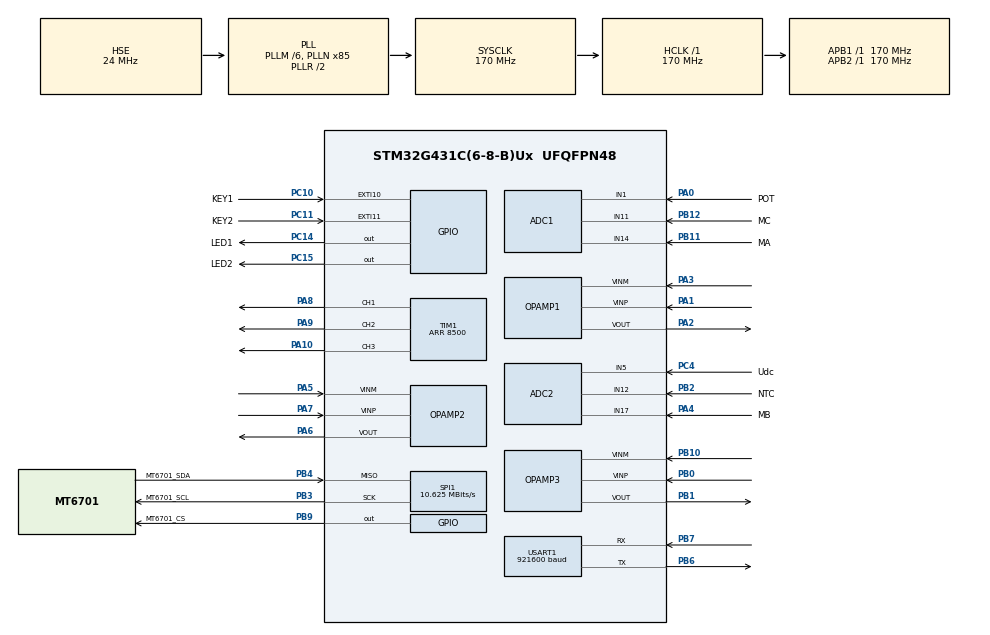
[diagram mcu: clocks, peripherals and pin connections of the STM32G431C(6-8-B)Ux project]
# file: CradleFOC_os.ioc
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ADC1.Channel-0\#ChannelRegularConversion=ADC_CHANNEL_1
ADC1.Channel-1\#ChannelRegularConversion=ADC_CHANNEL_11
ADC1.Channel-2\#ChannelRegularConversion=ADC_CHANNEL_14
ADC1.ClockPrescaler=ADC_CLOCK_ASYNC_DIV6
ADC1.ContinuousConvMode=DISABLE
ADC1.DMAContinuousRequests=ENABLE
ADC1.EnableInjectedConversion=ENABLE
ADC1.ExternalTrigConv=ADC_EXTERNALTRIG_T2_CC2
ADC1.ExternalTrigInjecConv=ADC_EXTERNALTRIGINJEC_T1_CC4
ADC1.InjNumberOfConversion=2
ADC1.InjectedChannel-3\#ChannelInjectedConversion=ADC_CHANNEL_3
ADC1.InjectedChannel-4\#ChannelInjectedConversion=ADC_CHANNEL_12
ADC1.InjectedOffsetNumber-3\#ChannelInjectedConversion=ADC_OFFSET_NONE
ADC1.InjectedOffsetNumber-4\#ChannelInjectedConversion=ADC_OFFSET_NONE
ADC1.InjectedRank-3\#ChannelInjectedConversion=1
ADC1.InjectedRank-4\#ChannelInjectedConversion=2
ADC1.InjectedSamplingTime-3\#ChannelInjectedConversion=ADC_SAMPLETIME_12CYCLES_5
ADC1.InjectedSamplingTime-4\#ChannelInjectedConversion=ADC_SAMPLETIME_12CYCLES_5
ADC1.NbrOfConversion=3
ADC1.NbrOfConversionFlag=1
ADC1.OffsetNumber-0\#ChannelRegularConversion=ADC_OFFSET_NONE
ADC1.OffsetNumber-1\#ChannelRegularConversion=ADC_OFFSET_NONE
ADC1.OffsetNumber-2\#ChannelRegularConversion=ADC_OFFSET_NONE
ADC1.Rank-0\#ChannelRegularConversion=1
ADC1.Rank-1\#ChannelRegularConversion=2
ADC1.Rank-2\#ChannelRegularConversion=3
ADC1.Rank1_Channel=ADC_CHANNEL_3
ADC1.Rank2_Channel=ADC_CHANNEL_12
ADC1.SamplingTime-0\#ChannelRegularConversion=ADC_SAMPLETIME_12CYCLES_5
ADC1.SamplingTime-1\#ChannelRegularConversion=ADC_SAMPLETIME_12CYCLES_5
ADC1.SamplingTime-2\#ChannelRegularConversion=ADC_SAMPLETIME_12CYCLES_5
ADC1.master=1
ADC2.Channel-0\#ChannelRegularConversion=ADC_CHANNEL_5
ADC2.Channel-1\#ChannelRegularConversion=ADC_CHANNEL_12
ADC2.Channel-2\#ChannelRegularConversion=ADC_CHANNEL_17
ADC2.ClockPrescaler=ADC_CLOCK_ASYNC_DIV6
ADC2.ContinuousConvMode=DISABLE
ADC2.DMAContinuousRequests=ENABLE
ADC2.EnableInjectedConversion=ENABLE
ADC2.ExternalTrigConv=ADC_EXTERNALTRIG_T2_CC2
ADC2.ExternalTrigInjecConv=ADC_EXTERNALTRIGINJEC_T1_CC4
ADC2.InjNumberOfConversion=1
ADC2.InjectedChannel-3\#ChannelInjectedConversion=ADC_CHANNEL_3
ADC2.InjectedOffsetNumber-3\#ChannelInjectedConversion=ADC_OFFSET_NONE
ADC2.InjectedRank-3\#ChannelInjectedConversion=1
ADC2.InjectedSamplingTime-3\#ChannelInjectedConversion=ADC_SAMPLETIME_12CYCLES_5
ADC2.NbrOfConversion=3
ADC2.NbrOfConversionFlag=1
ADC2.OffsetNumber-0\#ChannelRegularConversion=ADC_OFFSET_NONE
ADC2.OffsetNumber-1\#ChannelRegularConversion=ADC_OFFSET_NONE
ADC2.OffsetNumber-2\#ChannelRegularConversion=ADC_OFFSET_NONE
ADC2.Rank-0\#ChannelRegularConversion=1
ADC2.Rank-1\#ChannelRegularConversion=2
ADC2.Rank-2\#ChannelRegularConversion=3
ADC2.Rank1_Channel=ADC_CHANNEL_3
ADC2.SamplingTime-0\#ChannelRegularConversion=ADC_SAMPLETIME_12CYCLES_5
ADC2.SamplingTime-1\#ChannelRegularConversion=ADC_SAMPLETIME_12CYCLES_5
ADC2.SamplingTime-2\#ChannelRegularConversion=ADC_SAMPLETIME_12CYCLES_5
Dma.ADC1.1.Direction=DMA_PERIPH_TO_MEMORY
Dma.ADC1.1.EventEnable=DISABLE
Dma.ADC1.1.Instance=DMA1_Channel2
Dma.ADC1.1.MemDataAlignment=DMA_MDATAALIGN_HALFWORD
Dma.ADC1.1.MemInc=DMA_MINC_ENABLE
Dma.ADC1.1.Mode=DMA_CIRCULAR
Dma.ADC1.1.PeriphDataAlignment=DMA_PDATAALIGN_HALFWORD
Dma.ADC1.1.PeriphInc=DMA_PINC_DISABLE
Dma.ADC1.1.Polarity=HAL_DMAMUX_REQ_GEN_RISING
Dma.ADC1.1.Priority=DMA_PRIORITY_LOW
Dma.ADC1.1.RequestNumber=1
Dma.ADC1.1.SignalID=NONE
Dma.ADC1.1.SyncEnable=DISABLE
Dma.ADC1.1.SyncPolarity=HAL_DMAMUX_SYNC_NO_EVENT
Dma.ADC1.1.SyncRequestNumber=1
Dma.ADC1.1.SyncSignalID=NONE
Dma.ADC2.2.Direction=DMA_PERIPH_TO_MEMORY
Dma.ADC2.2.EventEnable=DISABLE
Dma.ADC2.2.Instance=DMA1_Channel3
Dma.ADC2.2.MemDataAlignment=DMA_MDATAALIGN_HALFWORD
Dma.ADC2.2.MemInc=DMA_MINC_ENABLE
Dma.ADC2.2.Mode=DMA_CIRCULAR
Dma.ADC2.2.PeriphDataAlignment=DMA_PDATAALIGN_HALFWORD
Dma.ADC2.2.PeriphInc=DMA_PINC_DISABLE
Dma.ADC2.2.Polarity=HAL_DMAMUX_REQ_GEN_RISING
Dma.ADC2.2.Priority=DMA_PRIORITY_LOW
Dma.ADC2.2.RequestNumber=1
Dma.ADC2.2.SignalID=NONE
Dma.ADC2.2.SyncEnable=DISABLE
Dma.ADC2.2.SyncPolarity=HAL_DMAMUX_SYNC_NO_EVENT
Dma.ADC2.2.SyncRequestNumber=1
Dma.ADC2.2.SyncSignalID=NONE
Dma.Request0=USART1_TX
Dma.Request1=ADC1
Dma.Request2=ADC2
Dma.USART1_TX.0.Direction=DMA_MEMORY_TO_PERIPH
Dma.USART1_TX.0.EventEnable=DISABLE
Dma.USART1_TX.0.Instance=DMA1_Channel1
Dma.USART1_TX.0.MemDataAlignment=DMA_MDATAALIGN_BYTE
Dma.USART1_TX.0.MemInc=DMA_MINC_ENABLE
Dma.USART1_TX.0.Mode=DMA_NORMAL
Dma.USART1_TX.0.PeriphDataAlignment=DMA_PDATAALIGN_BYTE
Dma.USART1_TX.0.PeriphInc=DMA_PINC_DISABLE
Dma.USART1_TX.0.Polarity=HAL_DMAMUX_REQ_GEN_RISING
Dma.USART1_TX.0.Priority=DMA_PRIORITY_LOW
Dma.USART1_TX.0.RequestNumber=1
Dma.USART1_TX.0.SignalID=NONE
Dma.USART1_TX.0.SyncEnable=DISABLE
Dma.USART1_TX.0.SyncPolarity=HAL_DMAMUX_SYNC_NO_EVENT
Dma.USART1_TX.0.SyncRequestNumber=1
Dma.USART1_TX.0.SyncSignalID=NONE
FREERTOS.INCLUDE_uxTaskGetStackHighWaterMark=1
FREERTOS.Tasks01=defaultTask,0,64,StartDefaultTask,Default,NULL,Dynamic,NULL,NULL;myTask02_LOG,-2,300,FOC_LOG,Default,NULL,Dynamic,NULL,NULL;myTask03_KEY,-2,64,KEY_USER,Default,NULL,Dynamic,NULL,NULL;myTask04_FOC,-1,200,FOC,Default,NULL,Dynamic,NULL,NULL
FREERTOS.configENABLE_FPU=1
FREERTOS.configMINIMAL_STACK_SIZE=64
FREERTOS.configTOTAL_HEAP_SIZE=5000
Mcu.Family=STM32G4
Mcu.Name=STM32G431C(6-8-B)Ux
Mcu.Package=UFQFPN48
NVIC.ADC1_2_IRQn=true\:5\:0\:false\:false\:true\:true\:true\:true\:true
NVIC.DMA1_Channel1_IRQn=true\:5\:0\:false\:false\:true\:true\:false\:true\:true
NVIC.DMA1_Channel2_IRQn=true\:5\:0\:false\:false\:true\:true\:false\:true\:true
NVIC.DMA1_Channel3_IRQn=true\:5\:0\:false\:false\:true\:true\:false\:true\:true
NVIC.EXTI15_10_IRQn=true\:5\:0\:false\:false\:true\:true\:true\:true\:true
NVIC.PriorityGroup=NVIC_PRIORITYGROUP_4
NVIC.TIM3_IRQn=true\:15\:0\:false\:false\:true\:false\:false\:true\:true
NVIC.TimeBase=TIM3_IRQn
NVIC.TimeBaseIP=TIM3
NVIC.USART1_IRQn=true\:5\:0\:false\:false\:true\:true\:true\:true\:true
PA0.GPIO_Label=POT
PA0.Mode=IN1-Single-Ended
PA0.Signal=ADC1_IN1
PA1.Mode=Standalone
PA1.Signal=OPAMP1_VINP
PA10.Signal=S_TIM1_CH3
PA13.Mode=Serial_Wire
PA13.Signal=SYS_JTMS-SWDIO
PA14.Mode=Serial_Wire
PA14.Signal=SYS_JTCK-SWCLK
PA2.Signal=SharedAnalog_PA2
PA3.Mode=Standalone
PA3.Signal=OPAMP1_VINM
PA4.GPIO_Label=MB
PA4.Mode=IN17-Single-Ended
PA4.Signal=ADC2_IN17
PA5.Mode=Standalone
PA5.Signal=OPAMP2_VINM
PA6.Signal=SharedAnalog_PA6
PA7.Mode=Standalone
PA7.Signal=OPAMP2_VINP
PA8.Signal=S_TIM1_CH1
PA9.Signal=S_TIM1_CH2
PB0.Mode=Standalone
PB0.Signal=OPAMP3_VINP
PB1.Signal=SharedAnalog_PB1
PB10.Mode=Standalone
PB10.Signal=OPAMP3_VINM
PB11.GPIO_Label=MA
PB11.Mode=IN14-Single-Ended
PB11.Signal=ADC1_IN14
PB12.GPIO_Label=MC
PB12.Mode=IN11-Single-Ended
PB12.Signal=ADC1_IN11
PB2.GPIO_Label=NTC
PB2.Mode=IN12-Single-Ended
PB2.Signal=ADC2_IN12
PB3.GPIO_Label=MT6701_SCL
PB3.Mode=RX_Only_Simplex_Unidirect_Master
PB3.Signal=SPI1_SCK
PB4.GPIO_Label=MT6701_SDA
PB4.Mode=RX_Only_Simplex_Unidirect_Master
PB4.Signal=SPI1_MISO
PB6.Mode=Asynchronous
PB6.Signal=USART1_TX
PB7.Mode=Asynchronous
PB7.Signal=USART1_RX
PB9.GPIO_Label=MT6701_CS
PB9.GPIO_Speed=GPIO_SPEED_FREQ_HIGH
PB9.PinState=GPIO_PIN_SET
PB9.Signal=GPIO_Output
PC10.GPIO_Label=KEY1
PC10.GPIO_ModeDefaultEXTI=GPIO_MODE_IT_FALLING
PC10.Signal=GPXTI10
PC11.GPIO_Label=KEY2
PC11.GPIO_ModeDefaultEXTI=GPIO_MODE_IT_FALLING
PC11.Signal=GPXTI11
PC14-OSC32_IN.GPIO_Label=LED1
PC14-OSC32_IN.PinState=GPIO_PIN_SET
PC14-OSC32_IN.Signal=GPIO_Output
PC15-OSC32_OUT.GPIO_Label=LED2
PC15-OSC32_OUT.PinState=GPIO_PIN_SET
PC15-OSC32_OUT.Signal=GPIO_Output
PC4.GPIO_Label=Udc
PC4.Mode=IN5-Single-Ended
PC4.Signal=ADC2_IN5
PF0-OSC_IN.Mode=HSE-External-Oscillator
PF0-OSC_IN.Signal=RCC_OSC_IN
PF1-OSC_OUT.Mode=HSE-External-Oscillator
PF1-OSC_OUT.Signal=RCC_OSC_OUT
ProjectManager.HeapSize=0x200
ProjectManager.StackSize=0x400
ProjectManager.TargetToolchain=STM32CubeIDE
RCC.ADC12Freq_Value=170000000
RCC.AHBFreq_Value=170000000
RCC.APB1Freq_Value=170000000
RCC.APB1TimFreq_Value=170000000
RCC.APB2Freq_Value=170000000
RCC.APB2TimFreq_Value=170000000
RCC.CortexFreq_Value=170000000
RCC.EXTERNAL_CLOCK_VALUE=12288000
RCC.HCLKFreq_Value=170000000
RCC.HSE_VALUE=24000000
RCC.HSI48_VALUE=48000000
RCC.HSI_VALUE=16000000
RCC.LSE_VALUE=32768
RCC.PLLM=RCC_PLLM_DIV6
RCC.PLLN=85
RCC.PLLSourceVirtual=RCC_PLLSOURCE_HSE
RCC.SYSCLKFreq_VALUE=170000000
RCC.SYSCLKSource=RCC_SYSCLKSOURCE_PLLCLK
RCC.USBFreq_Value=170000000
RCC.VCOOutputFreq_Value=340000000
SH.S_TIM1_CH1.0=TIM1_CH1,PWM Generation1 CH1
SH.S_TIM1_CH2.0=TIM1_CH2,PWM Generation2 CH2
SH.S_TIM1_CH3.0=TIM1_CH3,PWM Generation3 CH3
SH.SharedAnalog_PA2.0=OPAMP1_VOUT,Standalone
SH.SharedAnalog_PA2.1=ADC1_IN3,IN3-Single-Ended
SH.SharedAnalog_PA6.0=OPAMP2_VOUT,Standalone
SH.SharedAnalog_PA6.1=ADC2_IN3,IN3-Single-Ended
SH.SharedAnalog_PB1.0=OPAMP3_VOUT,Standalone
SH.SharedAnalog_PB1.1=ADC1_IN12,IN12-Single-Ended
SPI1.BaudRatePrescaler=SPI_BAUDRATEPRESCALER_16
SPI1.CLKPhase=SPI_PHASE_2EDGE
SPI1.CalculateBaudRate=10.625 MBits/s
SPI1.DataSize=SPI_DATASIZE_16BIT
SPI1.Direction=SPI_DIRECTION_2LINES_RXONLY
SPI1.Mode=SPI_MODE_MASTER
SPI1.VirtualType=VM_MASTER
STMicroelectronics.X-CUBE-ALGOBUILD.1.3.0.LibraryCcDSPOoLibraryJjDSPOoLibrary=true
TIM1.Channel-PWM\ Generation1\ CH1=TIM_CHANNEL_1
TIM1.Channel-PWM\ Generation2\ CH2=TIM_CHANNEL_2
TIM1.Channel-PWM\ Generation3\ CH3=TIM_CHANNEL_3
TIM1.Channel-PWM\ Generation4\ No\ Output=TIM_CHANNEL_4
TIM1.CounterMode=TIM_COUNTERMODE_CENTERALIGNED1
TIM1.OCMode_PWM-PWM\ Generation4\ No\ Output=TIM_OCMODE_PWM2
TIM1.PeriodNoDither=8500
TIM1.RepetitionCounter=1
TIM1.TIM_MasterOutputTrigger=TIM_TRGO_OC4REF
TIM2.Channel-PWM\ Generation2\ No\ Output=TIM_CHANNEL_2
TIM2.OCMode_PWM-PWM\ Generation2\ No\ Output=TIM_OCMODE_PWM2
TIM2.PeriodNoDither=1000-1
TIM2.Prescaler=170-1
TIM2.TIM_MasterOutputTrigger=TIM_TRGO_OC2REF
USART1.BaudRate=921600
USART1.VirtualMode-Asynchronous=VM_ASYNC
VP_FREERTOS_VS_CMSIS_V1.Mode=CMSIS_V1
VP_STMicroelectronics.X-CUBE-ALGOBUILD_VS_DSPOoLibraryJjLibrary_1.3.0_1.3.0.Mode=DSPOoLibraryJjLibrary
VP_SYS_VS_DBSignals.Mode=DisableDeadBatterySignals
VP_SYS_VS_tim3.Mode=TIM3
VP_TIM1_VS_ClockSourceINT.Mode=Internal
VP_TIM1_VS_no_output4.Mode=PWM Generation4 No Output
VP_TIM2_VS_ClockSourceINT.Mode=Internal
VP_TIM2_VS_no_output2.Mode=PWM Generation2 No Output
board=custom

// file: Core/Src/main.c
/* USER CODE BEGIN Header */
/**
  ******************************************************************************
  * @file           : main.c
  * @brief          : Main program body
  ******************************************************************************
  * @attention
  *
  * Copyright (c) 2024 STMicroelectronics.
  * All rights reserved.
  *
  * This software is licensed under terms that can be found in the LICENSE file
  * in the root directory of this software component.
  * If no LICENSE file comes with this software, it is provided AS-IS.
  *
  ******************************************************************************
  */
/* USER CODE END Header */
#include "main.h"
#include "cmsis_os.h"
#include "adc.h"
#include "dma.h"
#include "opamp.h"
#include "spi.h"
#include "tim.h"
#include "usart.h"
#include "gpio.h"

void SystemClock_Config(void);
void MX_FREERTOS_Init(void);

int main(void)
{

  /* MCU Configuration--------------------------------------------------------*/

  /* Reset of all peripherals, Initializes the Flash interface and the Systick. */
  HAL_Init();

  /* Configure the system clock */
  SystemClock_Config();

  /* Initialize all configured peripherals */
  MX_GPIO_Init();
  MX_DMA_Init();
  MX_USART1_UART_Init();
  MX_TIM1_Init();
  MX_SPI1_Init();
  MX_ADC1_Init();
  MX_ADC2_Init();
  MX_TIM2_Init();
  MX_OPAMP1_Init();
  MX_OPAMP2_Init();
  MX_OPAMP3_Init();

  /* Call init function for freertos objects (in freertos.c) */
  MX_FREERTOS_Init();

  /* Start scheduler */
  osKernelStart();

  /* We should never get here as control is now taken by the scheduler */
  /* Infinite loop */
  while (1)
  {

  }
}

void SystemClock_Config(void)
{
  RCC_OscInitTypeDef RCC_OscInitStruct = {0};
  RCC_ClkInitTypeDef RCC_ClkInitStruct = {0};

  /** Configure the main internal regulator output voltage
  */
  HAL_PWREx_ControlVoltageScaling(PWR_REGULATOR_VOLTAGE_SCALE1_BOOST);

  /** Initializes the RCC Oscillators according to the specified parameters
  * in the RCC_OscInitTypeDef structure.
  */
  RCC_OscInitStruct.OscillatorType = RCC_OSCILLATORTYPE_HSE;
  RCC_OscInitStruct.HSEState = RCC_HSE_ON;
  RCC_OscInitStruct.PLL.PLLState = RCC_PLL_ON;
  RCC_OscInitStruct.PLL.PLLSource = RCC_PLLSOURCE_HSE;
  RCC_OscInitStruct.PLL.PLLM = RCC_PLLM_DIV6;
  RCC_OscInitStruct.PLL.PLLN = 85;
  RCC_OscInitStruct.PLL.PLLP = RCC_PLLP_DIV2;
  RCC_OscInitStruct.PLL.PLLQ = RCC_PLLQ_DIV2;
  RCC_OscInitStruct.PLL.PLLR = RCC_PLLR_DIV2;
  if (HAL_RCC_OscConfig(&RCC_OscInitStruct) != HAL_OK)
  {
    Error_Handler();
  }

  /** Initializes the CPU, AHB and APB buses clocks
  */
  RCC_ClkInitStruct.ClockType = RCC_CLOCKTYPE_HCLK|RCC_CLOCKTYPE_SYSCLK
                              |RCC_CLOCKTYPE_PCLK1|RCC_CLOCKTYPE_PCLK2;
  RCC_ClkInitStruct.SYSCLKSource = RCC_SYSCLKSOURCE_PLLCLK;
  RCC_ClkInitStruct.AHBCLKDivider = RCC_SYSCLK_DIV1;
  RCC_ClkInitStruct.APB1CLKDivider = RCC_HCLK_DIV1;
  RCC_ClkInitStruct.APB2CLKDivider = RCC_HCLK_DIV1;

  if (HAL_RCC_ClockConfig(&RCC_ClkInitStruct, FLASH_LATENCY_4) != HAL_OK)
  {
    Error_Handler();
  }
}

void HAL_TIM_PeriodElapsedCallback(TIM_HandleTypeDef *htim)
{
  if (htim->Instance == TIM3) {
    HAL_IncTick();
  }
}

void Error_Handler(void)
{
  __disable_irq();
  while (1)
  {
  }
}

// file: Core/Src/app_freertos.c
/* USER CODE BEGIN Header */
/**
  ******************************************************************************
  * File Name          : app_freertos.c
  * Description        : Code for freertos applications
  ******************************************************************************
  * @attention
  *
  * Copyright (c) 2024 STMicroelectronics.
  * All rights reserved.
  *
  * This software is licensed under terms that can be found in the LICENSE file
  * in the root directory of this software component.
  * If no LICENSE file comes with this software, it is provided AS-IS.
  *
  ******************************************************************************
  */
/* USER CODE END Header */

#include "FreeRTOS.h"
#include "task.h"
#include "main.h"
#include "cmsis_os.h"

/* USER CODE BEGIN Includes */
#include "UserAPP.h"
#include "Serial.h"
/* USER CODE END Includes */

osThreadId defaultTaskHandle;
osThreadId myTask02_LOGHandle;
osThreadId myTask03_KEYHandle;
osThreadId myTask04_FOCHandle;

void StartDefaultTask(void const * argument);
void FOC_LOG(void const * argument);
void KEY_USER(void const * argument);
void FOC(void const * argument);

void MX_FREERTOS_Init(void); /* (MISRA C 2004 rule 8.1) */

void MX_FREERTOS_Init(void) {
  /* USER CODE BEGIN Init */
    setup();
  /* USER CODE END Init */

  /* Create the thread(s) */
  /* definition and creation of defaultTask */
  osThreadDef(defaultTask, StartDefaultTask, osPriorityNormal, 0, 64);
  defaultTaskHandle = osThreadCreate(osThread(defaultTask), NULL);

  /* definition and creation of myTask02_LOG */
  osThreadDef(myTask02_LOG, FOC_LOG, osPriorityLow, 0, 300);
  myTask02_LOGHandle = osThreadCreate(osThread(myTask02_LOG), NULL);

  /* definition and creation of myTask03_KEY */
  osThreadDef(myTask03_KEY, KEY_USER, osPriorityLow, 0, 64);
  myTask03_KEYHandle = osThreadCreate(osThread(myTask03_KEY), NULL);

  /* definition and creation of myTask04_FOC */
  osThreadDef(myTask04_FOC, FOC, osPriorityBelowNormal, 0, 200);
  myTask04_FOCHandle = osThreadCreate(osThread(myTask04_FOC), NULL);

}

void StartDefaultTask(void const * argument)
{
    for (;;) {
        osDelay(1);
    }
}

void FOC_LOG(void const * argument)
{
  /* USER CODE BEGIN FOC_LOG */
    /* Infinite loop */
    for (;;) {
        task_log();
        osDelay(1);
    }
  /* USER CODE END FOC_LOG */
}

void KEY_USER(void const * argument)
{
  /* USER CODE BEGIN KEY_USER */
    /* Infinite loop */
    for (;;) {
        task_key();
        osDelay(1);
    }
  /* USER CODE END KEY_USER */
}

void FOC(void const * argument)
{
  /* USER CODE BEGIN FOC */
    /* Infinite loop */
    for (;;) {
        task_FOC();
        osDelay(1);
    }
  /* USER CODE END FOC */
}
